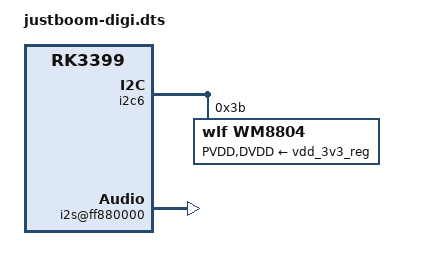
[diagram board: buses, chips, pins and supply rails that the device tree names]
/dts-v1/;
/plugin/;

/ {
	compatible = "rockchip,rk3399";

	fragment@0 {
		target = <&dp_sound>;
		__overlay__ {
			status = "disabled";
		};
	};

	fragment@1 {
		target = <&hdmi_sound>;
		__overlay__ {
			status = "disabled";
		};
	};

	fragment@2 {
		target = <&i2c6>;
		__overlay__ {
			#address-cells = <1>;
			#size-cells = <0>;
			status = "okay";

			wm8804@3b {
				#sound-dai-cells = <0>;
				compatible = "wlf,wm8804";
				reg = <0x3b>;
				PVDD-supply = <&vdd_3v3_reg>;
				DVDD-supply = <&vdd_3v3_reg>;
				status = "okay";
			};
		};
	};

	fragment@3 {
		target-path ="/i2s@ff880000";
		__overlay__ {
			#sound-dai-cells = <0>;
			status = "okay";
		};
	};

	fragment@4 {
		target-path = "/sound-ext-card";
		__overlay__ {
			compatible = "justboom,justboom-digi";
			i2s-controller = <&i2s0>;
			status = "okay";
		};
	};
};
